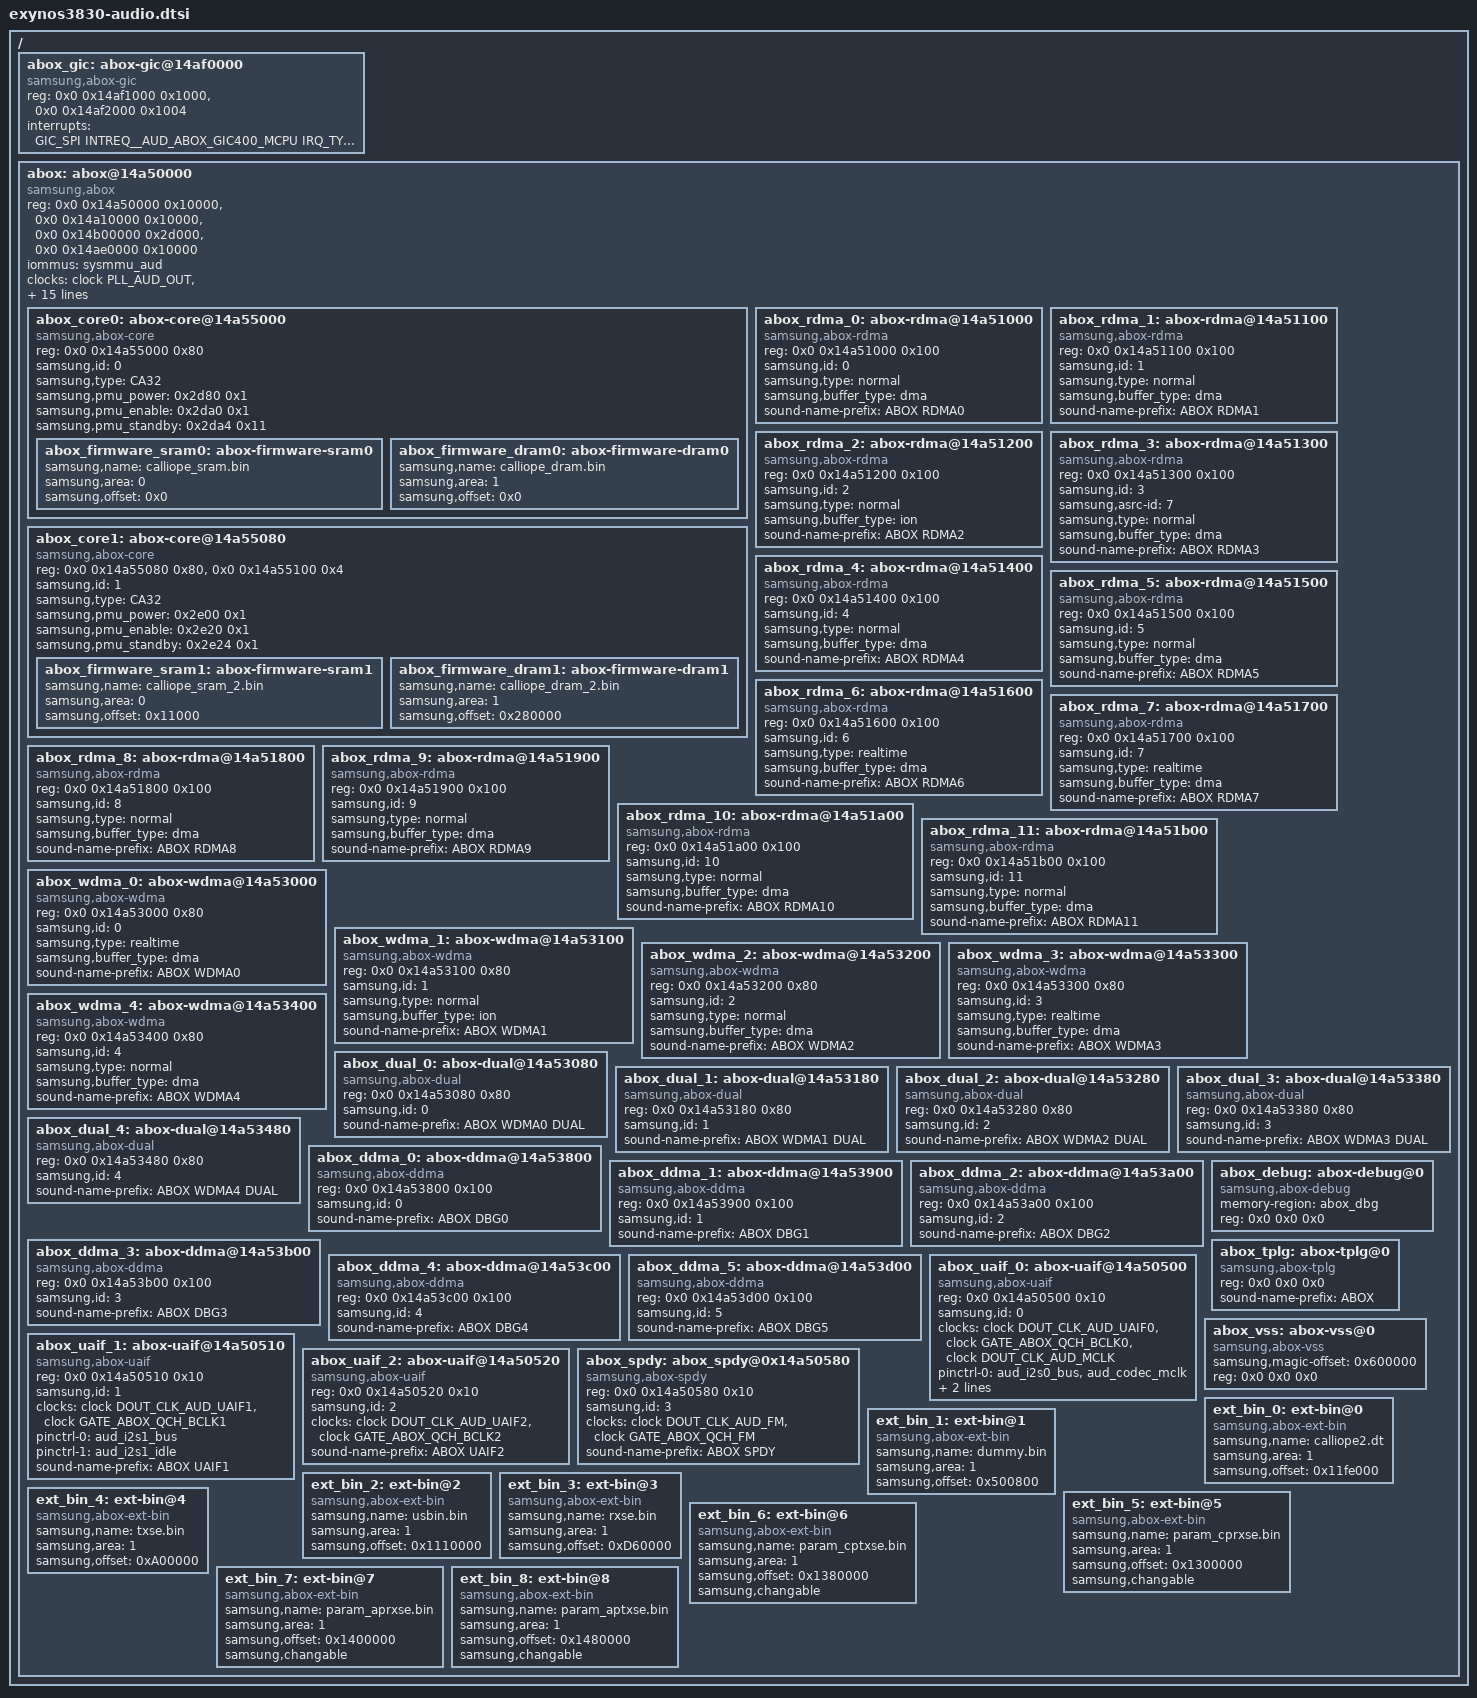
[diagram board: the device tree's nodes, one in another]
/*
 * Samsung's Exynos3830 SoC Audio device tree source
 *
 * Copyright (c) 2019 Samsung Electronics Co., Ltd.
 *		http://www.samsung.com
 *
 * Samsung's Exynos3830 SoC audio devices are listed.
 *
 * This program is free software; you can redistribute it and/or modify
 * it under the terms of the GNU General Public License version 2 as
 * published by the Free Software Foundation.
*/

/ {
	abox_gic: abox-gic@14af0000 {
		compatible = "samsung,abox-gic";
		reg = <0x0 0x14af1000 0x1000>, <0x0 0x14af2000 0x1004>;
		reg-names = "gicd", "gicc";
		interrupts = <GIC_SPI INTREQ__AUD_ABOX_GIC400_MCPU IRQ_TYPE_LEVEL_HIGH>;
	};

	abox: abox@14a50000 {
		compatible = "samsung,abox";
		reg = <0x0 0x14a50000 0x10000>, <0x0 0x14a10000 0x10000>,
			<0x0 0x14b00000 0x2d000>, <0x0 0x14ae0000 0x10000>;
		reg-names = "sfr", "sysreg", "sram", "timer";
		#address-cells = <2>;
		#size-cells = <1>;
		ranges;
		iommus = <&sysmmu_aud>;
		clocks = <&clock PLL_AUD_OUT>, <&clock DOUT_CLK_AUD_AUDIF>,
			<&clock DOUT_CLK_AUD_BUSD>, <&clock DOUT_CLK_AUD_CNT>;
		clock-names = "pll", "audif", "bus", "cnt";
		#sound-dai-cells = <1>;
		sound-name-prefix = "ABOX";
		samsung,quirks = "try to asrc off";
		samsung,ipc-tx-area = <0x1 0x850000 0x18000>;
		samsung,ipc-rx-area = <0x1 0x868000 0x18000>;
		samsung,shm-area = <0x1 0x8bc000 0x4000>;
		samsung,handshake-area = <0x0 0x23800 0x20>;
		samsung,drv-bootargs-area = <0x0 0x23E00 0x100>;
		samsung,abox-gic = <&abox_gic>;
		samsung,uaif-max-div = <512>;
		samsung,pm-qos-int = <0 0 0 0 0>;
		samsung,pm-qos-aud = <1033000 800000 517000 345000 0>;

		abox_core0: abox-core@14a55000 {
			compatible = "samsung,abox-core";
			reg = <0x0 0x14a55000 0x80>;
			reg-names = "gpr";
			samsung,id = <0>;
			samsung,type = "CA32";
			samsung,pmu_power = <0x2d80 0x1>; /* AUD_CPU0_CONFIGURATION */
			samsung,pmu_enable = <0x2da0 0x1>; /* AUD_CPU0_OUT */
			samsung,pmu_standby = <0x2da4 0x11>; /* AUD_CPU0_IN */
			abox_firmware_sram0: abox-firmware-sram0 {
				samsung,name = "calliope_sram.bin";
				samsung,area = <0>; /* 0:SRAM, 1:DRAM */
				samsung,offset = <0x0>;
			};
			abox_firmware_dram0: abox-firmware-dram0 {
				samsung,name = "calliope_dram.bin";
				samsung,area = <1>; /* 0:SRAM, 1:DRAM */
				samsung,offset = <0x0>;
			};
		};

		abox_core1: abox-core@14a55080 {
			compatible = "samsung,abox-core";
			reg = <0x0 0x14a55080 0x80>, <0x0 0x14a55100 0x4>;
			reg-names = "gpr", "status";
			samsung,id = <1>;
			samsung,type = "CA32";
			samsung,pmu_power = <0x2e00 0x1>; /* AUD_CPU1_CONFIGURATION */
			samsung,pmu_enable = <0x2e20 0x1>; /* AUD_CPU1_OUT */
			samsung,pmu_standby = <0x2e24 0x1>; /* AUD_CPU1_IN */
			abox_firmware_sram1: abox-firmware-sram1 {
				samsung,name = "calliope_sram_2.bin";
				samsung,area = <0>; /* 0:SRAM, 1:DRAM */
				samsung,offset = <0x11000>;
			};
			abox_firmware_dram1: abox-firmware-dram1 {
				samsung,name = "calliope_dram_2.bin";
				samsung,area = <1>; /* 0:SRAM, 1:DRAM */
				samsung,offset = <0x280000>;
			};
		};

		abox_rdma_0: abox-rdma@14a51000 {
			compatible = "samsung,abox-rdma";
			reg = <0x0 0x14a51000 0x100>;
			reg-names = "sfr";
			samsung,id = <0>;
			samsung,type = "normal";
			samsung,buffer_type = "dma";
			#sound-dai-cells = <1>;
			sound-name-prefix = "ABOX RDMA0";
		};

		abox_rdma_1: abox-rdma@14a51100 {
			compatible = "samsung,abox-rdma";
			reg = <0x0 0x14a51100 0x100>;
			reg-names = "sfr";
			samsung,id = <1>;
			samsung,type = "normal";
			samsung,buffer_type = "dma";
			#sound-dai-cells = <1>;
			sound-name-prefix = "ABOX RDMA1";
		};

		abox_rdma_2: abox-rdma@14a51200 {
			compatible = "samsung,abox-rdma";
			reg = <0x0 0x14a51200 0x100>;
			reg-names = "sfr";
			samsung,id = <2>;
			samsung,type = "normal";
			samsung,buffer_type = "ion";
			#sound-dai-cells = <1>;
			sound-name-prefix = "ABOX RDMA2";
		};

		abox_rdma_3: abox-rdma@14a51300 {
			compatible = "samsung,abox-rdma";
			reg = <0x0 0x14a51300 0x100>;
			reg-names = "sfr";
			samsung,id = <3>;
			samsung,asrc-id = <7>;
			samsung,type = "normal";
			samsung,buffer_type = "dma";
			#sound-dai-cells = <1>;
			sound-name-prefix = "ABOX RDMA3";
		};

		abox_rdma_4: abox-rdma@14a51400 {
			compatible = "samsung,abox-rdma";
			reg = <0x0 0x14a51400 0x100>;
			reg-names = "sfr";
			samsung,id = <4>;
			samsung,type = "normal";
			samsung,buffer_type = "dma";
			#sound-dai-cells = <1>;
			sound-name-prefix = "ABOX RDMA4";
		};

		abox_rdma_5: abox-rdma@14a51500 {
			compatible = "samsung,abox-rdma";
			reg = <0x0 0x14a51500 0x100>;
			reg-names = "sfr";
			samsung,id = <5>;
			samsung,type = "normal";
			samsung,buffer_type = "dma";
			#sound-dai-cells = <1>;
			sound-name-prefix = "ABOX RDMA5";
		};

		abox_rdma_6: abox-rdma@14a51600 {
			compatible = "samsung,abox-rdma";
			reg = <0x0 0x14a51600 0x100>;
			reg-names = "sfr";
			samsung,id = <6>;
			samsung,type = "realtime";
			samsung,buffer_type = "dma";
			#sound-dai-cells = <1>;
			sound-name-prefix = "ABOX RDMA6";
		};

		abox_rdma_7: abox-rdma@14a51700 {
			compatible = "samsung,abox-rdma";
			reg = <0x0 0x14a51700 0x100>;
			reg-names = "sfr";
			samsung,id = <7>;
			samsung,type = "realtime";
			samsung,buffer_type = "dma";
			#sound-dai-cells = <1>;
			sound-name-prefix = "ABOX RDMA7";
		};

		abox_rdma_8: abox-rdma@14a51800 {
			compatible = "samsung,abox-rdma";
			reg = <0x0 0x14a51800 0x100>;
			reg-names = "sfr";
			samsung,id = <8>;
			samsung,type = "normal";
			samsung,buffer_type = "dma";
			#sound-dai-cells = <1>;
			sound-name-prefix = "ABOX RDMA8";
		};

		abox_rdma_9: abox-rdma@14a51900 {
			compatible = "samsung,abox-rdma";
			reg = <0x0 0x14a51900 0x100>;
			reg-names = "sfr";
			samsung,id = <9>;
			samsung,type = "normal";
			samsung,buffer_type = "dma";
			#sound-dai-cells = <1>;
			sound-name-prefix = "ABOX RDMA9";
		};

		abox_rdma_10: abox-rdma@14a51a00 {
			compatible = "samsung,abox-rdma";
			reg = <0x0 0x14a51a00 0x100>;
			reg-names = "sfr";
			samsung,id = <10>;
			samsung,type = "normal";
			samsung,buffer_type = "dma";
			#sound-dai-cells = <1>;
			sound-name-prefix = "ABOX RDMA10";
		};

		abox_rdma_11: abox-rdma@14a51b00 {
			compatible = "samsung,abox-rdma";
			reg = <0x0 0x14a51b00 0x100>;
			reg-names = "sfr";
			samsung,id = <11>;
			samsung,type = "normal";
			samsung,buffer_type = "dma";
			#sound-dai-cells = <1>;
			sound-name-prefix = "ABOX RDMA11";
		};

		abox_wdma_0: abox-wdma@14a53000 {
			compatible = "samsung,abox-wdma";
			reg = <0x0 0x14a53000 0x80>;
			reg-names = "sfr";
			samsung,id = <0>;
			samsung,type = "realtime";
			samsung,buffer_type = "dma";
			#sound-dai-cells = <1>;
			sound-name-prefix = "ABOX WDMA0";
		};

		abox_wdma_1: abox-wdma@14a53100 {
			compatible = "samsung,abox-wdma";
			reg = <0x0 0x14a53100 0x80>;
			reg-names = "sfr";
			samsung,id = <1>;
			samsung,type = "normal";
			samsung,buffer_type = "ion";
			#sound-dai-cells = <1>;
			sound-name-prefix = "ABOX WDMA1";
		};

		abox_wdma_2: abox-wdma@14a53200 {
			compatible = "samsung,abox-wdma";
			reg = <0x0 0x14a53200 0x80>;
			reg-names = "sfr";
			samsung,id = <2>;
			samsung,type = "normal";
			samsung,buffer_type = "dma";
			#sound-dai-cells = <1>;
			sound-name-prefix = "ABOX WDMA2";
		};

		abox_wdma_3: abox-wdma@14a53300 {
			compatible = "samsung,abox-wdma";
			reg = <0x0 0x14a53300 0x80>;
			reg-names = "sfr";
			samsung,id = <3>;
			samsung,type = "realtime";
			samsung,buffer_type = "dma";
			#sound-dai-cells = <1>;
			sound-name-prefix = "ABOX WDMA3";
		};

		abox_wdma_4: abox-wdma@14a53400 {
			compatible = "samsung,abox-wdma";
			reg = <0x0 0x14a53400 0x80>;
			reg-names = "sfr";
			samsung,id = <4>;
			samsung,type = "normal";
			samsung,buffer_type = "dma";
			#sound-dai-cells = <1>;
			sound-name-prefix = "ABOX WDMA4";
		};

		abox_dual_0: abox-dual@14a53080 {
			compatible = "samsung,abox-dual";
			reg = <0x0 0x14a53080 0x80>;
			reg-names = "sfr";
			samsung,id = <0>;
			#sound-dai-cells = <0>;
			sound-name-prefix = "ABOX WDMA0 DUAL";
		};

		abox_dual_1: abox-dual@14a53180 {
			compatible = "samsung,abox-dual";
			reg = <0x0 0x14a53180 0x80>;
			reg-names = "sfr";
			samsung,id = <1>;
			#sound-dai-cells = <0>;
			sound-name-prefix = "ABOX WDMA1 DUAL";
		};

		abox_dual_2: abox-dual@14a53280 {
			compatible = "samsung,abox-dual";
			reg = <0x0 0x14a53280 0x80>;
			reg-names = "sfr";
			samsung,id = <2>;
			#sound-dai-cells = <0>;
			sound-name-prefix = "ABOX WDMA2 DUAL";
		};

		abox_dual_3: abox-dual@14a53380 {
			compatible = "samsung,abox-dual";
			reg = <0x0 0x14a53380 0x80>;
			reg-names = "sfr";
			samsung,id = <3>;
			#sound-dai-cells = <0>;
			sound-name-prefix = "ABOX WDMA3 DUAL";
		};

		abox_dual_4: abox-dual@14a53480 {
			compatible = "samsung,abox-dual";
			reg = <0x0 0x14a53480 0x80>;
			reg-names = "sfr";
			samsung,id = <4>;
			#sound-dai-cells = <0>;
			sound-name-prefix = "ABOX WDMA4 DUAL";
		};

		abox_ddma_0: abox-ddma@14a53800 {
			compatible = "samsung,abox-ddma";
			reg = <0x0 0x14a53800 0x100>;
			reg-names = "sfr";
			samsung,id = <0>;
			#sound-dai-cells = <0>;
			sound-name-prefix = "ABOX DBG0";
		};

		abox_ddma_1: abox-ddma@14a53900 {
			compatible = "samsung,abox-ddma";
			reg = <0x0 0x14a53900 0x100>;
			reg-names = "sfr";
			samsung,id = <1>;
			#sound-dai-cells = <0>;
			sound-name-prefix = "ABOX DBG1";
		};

		abox_ddma_2: abox-ddma@14a53a00 {
			compatible = "samsung,abox-ddma";
			reg = <0x0 0x14a53a00 0x100>;
			reg-names = "sfr";
			samsung,id = <2>;
			#sound-dai-cells = <0>;
			sound-name-prefix = "ABOX DBG2";
		};

		abox_ddma_3: abox-ddma@14a53b00 {
			compatible = "samsung,abox-ddma";
			reg = <0x0 0x14a53b00 0x100>;
			reg-names = "sfr";
			samsung,id = <3>;
			#sound-dai-cells = <0>;
			sound-name-prefix = "ABOX DBG3";
		};

		abox_ddma_4: abox-ddma@14a53c00 {
			compatible = "samsung,abox-ddma";
			reg = <0x0 0x14a53c00 0x100>;
			reg-names = "sfr";
			samsung,id = <4>;
			#sound-dai-cells = <0>;
			sound-name-prefix = "ABOX DBG4";
		};

		abox_ddma_5: abox-ddma@14a53d00 {
			compatible = "samsung,abox-ddma";
			reg = <0x0 0x14a53d00 0x100>;
			reg-names = "sfr";
			samsung,id = <5>;
			#sound-dai-cells = <0>;
			sound-name-prefix = "ABOX DBG5";
		};

		abox_uaif_0: abox-uaif@14a50500 {
			compatible = "samsung,abox-uaif";
			reg = <0x0 0x14a50500 0x10>;
			reg-names = "sfr";
			samsung,id = <0>;
			clocks = <&clock DOUT_CLK_AUD_UAIF0>, <&clock GATE_ABOX_QCH_BCLK0>,
			       	<&clock DOUT_CLK_AUD_MCLK>;
			clock-names = "bclk", "bclk_gate", "mclk";
			pinctrl-names = "active", "idle";
			pinctrl-0 = <&aud_i2s0_bus &aud_codec_mclk>;
			pinctrl-1 = <&aud_i2s0_idle &aud_codec_mclk_idle>;
			#sound-dai-cells = <0>;
			sound-name-prefix = "ABOX UAIF0";
		};

		abox_uaif_1: abox-uaif@14a50510 {
			compatible = "samsung,abox-uaif";
			reg = <0x0 0x14a50510 0x10>;
			reg-names = "sfr";
			samsung,id = <1>;
			clocks = <&clock DOUT_CLK_AUD_UAIF1>, <&clock GATE_ABOX_QCH_BCLK1>;
			clock-names = "bclk", "bclk_gate";
			pinctrl-names = "active", "idle";
			pinctrl-0 = <&aud_i2s1_bus>;
			pinctrl-1 = <&aud_i2s1_idle>;
			#sound-dai-cells = <0>;
			sound-name-prefix = "ABOX UAIF1";
		};

		abox_uaif_2: abox-uaif@14a50520 {
			compatible = "samsung,abox-uaif";
			reg = <0x0 0x14a50520 0x10>;
			reg-names = "sfr";
			samsung,id = <2>;
			clocks = <&clock DOUT_CLK_AUD_UAIF2>, <&clock GATE_ABOX_QCH_BCLK2>;
			clock-names = "bclk", "bclk_gate";
			#sound-dai-cells = <0>;
			sound-name-prefix = "ABOX UAIF2";
		};

		abox_spdy: abox_spdy@0x14a50580 {
			compatible = "samsung,abox-spdy";
			reg = <0x0 0x14a50580 0x10>;
			reg-names = "sfr";
			samsung,id = <3>;
			clocks = <&clock DOUT_CLK_AUD_FM>, <&clock GATE_ABOX_QCH_FM>;
			clock-names = "bclk", "bclk_gate";
			/*pinctrl-names = "default", "sleep";
			pinctrl-0 = <&aud_fm_bus>;
			pinctrl-1 = <&aud_fm_idle>;*/
			#sound-dai-cells = <0>;
			sound-name-prefix = "ABOX SPDY";
		};

		abox_debug: abox-debug@0 {
			compatible = "samsung,abox-debug";
			memory-region = <&abox_dbg>;
			reg = <0x0 0x0 0x0>;
		};

		abox_tplg: abox-tplg@0 {
			compatible = "samsung,abox-tplg";
			reg = <0x0 0x0 0x0>;
			sound-name-prefix = "ABOX";
		};

		abox_vss: abox-vss@0 {
			compatible = "samsung,abox-vss";
			samsung,magic-offset = <0x600000>;
			reg = <0x0 0x0 0x0>;
		};

		ext_bin_0: ext-bin@0 {
			compatible = "samsung,abox-ext-bin";
			samsung,name = "calliope2.dt";
			samsung,area = <1>; /* 0:SRAM, 1:DRAM, 2:VSS */
			samsung,offset = <0x11fe000>;
		};
		ext_bin_1: ext-bin@1 {
			compatible = "samsung,abox-ext-bin";
			samsung,name = "dummy.bin";
			samsung,area = <1>;
			samsung,offset = <0x500800>;
		};
		ext_bin_2: ext-bin@2 {
			compatible = "samsung,abox-ext-bin";
			samsung,name = "usbin.bin";
			samsung,area = <1>;
			samsung,offset = <0x1110000>;
		};
		ext_bin_3: ext-bin@3 {
			compatible = "samsung,abox-ext-bin";
			samsung,name = "rxse.bin";
			samsung,area = <1>;
			samsung,offset = <0xD60000>;
		};
		ext_bin_4: ext-bin@4 {
			compatible = "samsung,abox-ext-bin";
			samsung,name = "txse.bin";
			samsung,area = <1>;
			samsung,offset = <0xA00000>;
		};
		ext_bin_5: ext-bin@5 {
			compatible = "samsung,abox-ext-bin";
			samsung,name = "param_cprxse.bin";
			samsung,area = <1>;
			samsung,offset = <0x1300000>;
			samsung,changable;
		};
		ext_bin_6: ext-bin@6 {
			compatible = "samsung,abox-ext-bin";
			samsung,name = "param_cptxse.bin";
			samsung,area = <1>;
			samsung,offset = <0x1380000>;
			samsung,changable;
		};
		ext_bin_7: ext-bin@7 {
			compatible = "samsung,abox-ext-bin";
			samsung,name = "param_aprxse.bin";
			samsung,area = <1>;
			samsung,offset = <0x1400000>;
			samsung,changable;
		};
		ext_bin_8: ext-bin@8 {
			compatible = "samsung,abox-ext-bin";
			samsung,name = "param_aptxse.bin";
			samsung,area = <1>;
			samsung,offset = <0x1480000>;
			samsung,changable;
		};
	};
};
